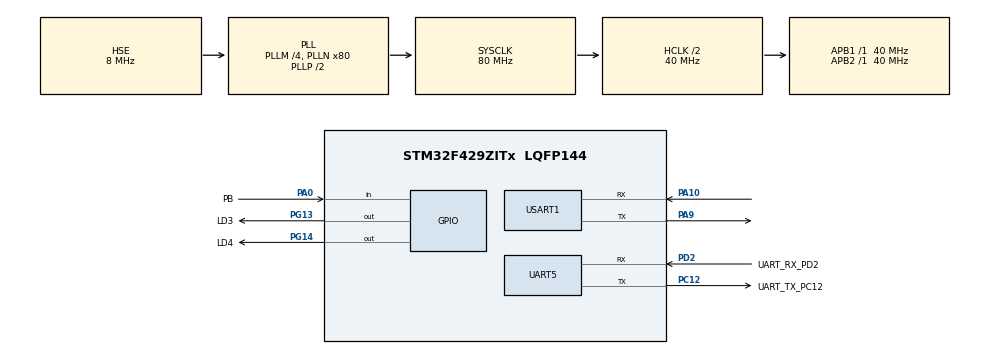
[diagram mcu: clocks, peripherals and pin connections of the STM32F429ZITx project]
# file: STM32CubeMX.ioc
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Mcu.Family=STM32F4
Mcu.Name=STM32F429ZITx
Mcu.Package=LQFP144
NVIC.PriorityGroup=NVIC_PRIORITYGROUP_4
PA0/WKUP.GPIO_Label=PB
PA0/WKUP.Signal=GPIO_Input
PA10.Mode=Asynchronous
PA10.Signal=USART1_RX
PA13.Mode=JTAG_4_pins
PA13.Signal=SYS_JTMS-SWDIO
PA14.Mode=JTAG_4_pins
PA14.Signal=SYS_JTCK-SWCLK
PA15.Mode=JTAG_4_pins
PA15.Signal=SYS_JTDI
PA9.Mode=Asynchronous
PA9.Signal=USART1_TX
PB3.Mode=JTAG_4_pins
PB3.Signal=SYS_JTDO-SWO
PC12.GPIO_Label=UART_TX_PC12
PC12.Mode=Asynchronous
PC12.Signal=UART5_TX
PD2.GPIO_Label=UART_RX_PD2
PD2.Mode=Asynchronous
PD2.Signal=UART5_RX
PG13.GPIO_Label=LD3
PG13.Signal=GPIO_Output
PG14.GPIO_Label=LD4
PG14.Signal=GPIO_Output
PH0/OSC_IN.Mode=HSE-External-Oscillator
PH0/OSC_IN.Signal=RCC_OSC_IN
PH1/OSC_OUT.Mode=HSE-External-Oscillator
PH1/OSC_OUT.Signal=RCC_OSC_OUT
ProjectManager.HeapSize=0x200
ProjectManager.StackSize=0x400
ProjectManager.TargetToolchain=MDK-ARM V5
RCC.48MHZClocksFreq_Value=40000000
RCC.AHBCLKDivider=RCC_SYSCLK_DIV2
RCC.AHBFreq_Value=40000000
RCC.APB1Freq_Value=40000000
RCC.APB1TimFreq_Value=40000000
RCC.APB2Freq_Value=40000000
RCC.APB2TimFreq_Value=40000000
RCC.CortexFreq_Value=40000000
RCC.HCLKFreq_Value=40000000
RCC.HSE_VALUE=8000000
RCC.HSI_VALUE=16000000
RCC.LSE_VALUE=32768
RCC.PLLM=4
RCC.PLLN=80
RCC.PLLSourceVirtual=RCC_PLLSOURCE_HSE
RCC.SYSCLKFreq_VALUE=80000000
RCC.SYSCLKSource=RCC_SYSCLKSOURCE_PLLCLK
RCC.VCOOutputFreq_Value=160000000
UART5.VirtualMode=Asynchronous
USART1.VirtualMode=VM_ASYNC
board=custom

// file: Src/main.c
/* USER CODE BEGIN Header */
/**
  ******************************************************************************
  * @file           : main.c
  * @brief          : Main program body
  ******************************************************************************
  * @attention
  *
  * Copyright (c) 2025 STMicroelectronics.
  * All rights reserved.
  *
  * This software is licensed under terms that can be found in the LICENSE file
  * in the root directory of this software component.
  * If no LICENSE file comes with this software, it is provided AS-IS.
  *
  ******************************************************************************
  */
/* USER CODE END Header */
#include "main.h"

/* USER CODE BEGIN Includes */
#include "uart.h"
#include "led.h"
/* USER CODE END Includes */

/* USER CODE BEGIN PTD */
Led_Type led1;
Led_Type led2;
/* USER CODE END PTD */

UART_HandleTypeDef huart5;
UART_HandleTypeDef huart1;

void SystemClock_Config(void);
static void MX_GPIO_Init(void);
static void MX_UART5_Init(void);
static void MX_USART1_UART_Init(void);

/* USER CODE BEGIN 0 */
char RData[15] = "Ramkumar\n\r";
/* USER CODE END 0 */

int main(void)
{

  /* MCU Configuration--------------------------------------------------------*/

  /* Reset of all peripherals, Initializes the Flash interface and the Systick. */
  HAL_Init();

  /* Configure the system clock */
  SystemClock_Config();

  /* Initialize all configured peripherals */
  MX_GPIO_Init();
  MX_UART5_Init();
  MX_USART1_UART_Init();

  /* Infinite loop */
  /* USER CODE BEGIN WHILE */
	printf("Hello there from main function\n\r");

	//HAL_UART_Transmit(&huart5, (uint8_t*)&RData, 1, HAL_MAX_DELAY);
	Led_ctor(&led1,RED,OFF);
	Led_ctor(&led2,GREEN,ON);

	Led_getState(&led1);
	Led_getState(&led2);

	Led_setState(&led1,ON);
	Led_setState(&led2,OFF);
  while (1)
  {
		//HAL_UART_Transmit(&huart5, (uint8_t*)RData, 20, HAL_MAX_DELAY);
		//printf("Hello there from main function\n\r");
		/*HAL_GPIO_ReadPin(GPIO_TypeDef* GPIOx, uint16_t GPIO_Pin)*/
	  //if(HAL_GPIO_ReadPin(GPIOA, PB_Pin))
		//  HAL_GPIO_WritePin(GPIOG, LD3_Pin, GPIO_PIN_SET);
	  //else
		//  HAL_GPIO_WritePin(GPIOG, LD3_Pin, GPIO_PIN_RESET);
    /* USER CODE END WHILE */

  }
}

void SystemClock_Config(void)
{
  RCC_OscInitTypeDef RCC_OscInitStruct = {0};
  RCC_ClkInitTypeDef RCC_ClkInitStruct = {0};

  /** Configure the main internal regulator output voltage
  */
  __HAL_RCC_PWR_CLK_ENABLE();
  __HAL_PWR_VOLTAGESCALING_CONFIG(PWR_REGULATOR_VOLTAGE_SCALE3);

  /** Initializes the RCC Oscillators according to the specified parameters
  * in the RCC_OscInitTypeDef structure.
  */
  RCC_OscInitStruct.OscillatorType = RCC_OSCILLATORTYPE_HSE;
  RCC_OscInitStruct.HSEState = RCC_HSE_ON;
  RCC_OscInitStruct.PLL.PLLState = RCC_PLL_ON;
  RCC_OscInitStruct.PLL.PLLSource = RCC_PLLSOURCE_HSE;
  RCC_OscInitStruct.PLL.PLLM = 4;
  RCC_OscInitStruct.PLL.PLLN = 80;
  RCC_OscInitStruct.PLL.PLLP = RCC_PLLP_DIV2;
  RCC_OscInitStruct.PLL.PLLQ = 4;
  if (HAL_RCC_OscConfig(&RCC_OscInitStruct) != HAL_OK)
  {
    Error_Handler();
  }

  /** Initializes the CPU, AHB and APB buses clocks
  */
  RCC_ClkInitStruct.ClockType = RCC_CLOCKTYPE_HCLK|RCC_CLOCKTYPE_SYSCLK
                              |RCC_CLOCKTYPE_PCLK1|RCC_CLOCKTYPE_PCLK2;
  RCC_ClkInitStruct.SYSCLKSource = RCC_SYSCLKSOURCE_PLLCLK;
  RCC_ClkInitStruct.AHBCLKDivider = RCC_SYSCLK_DIV2;
  RCC_ClkInitStruct.APB1CLKDivider = RCC_HCLK_DIV1;
  RCC_ClkInitStruct.APB2CLKDivider = RCC_HCLK_DIV1;

  if (HAL_RCC_ClockConfig(&RCC_ClkInitStruct, FLASH_LATENCY_1) != HAL_OK)
  {
    Error_Handler();
  }
}

static void MX_UART5_Init(void)
{

  huart5.Instance = UART5;
  huart5.Init.BaudRate = 115200;
  huart5.Init.WordLength = UART_WORDLENGTH_8B;
  huart5.Init.StopBits = UART_STOPBITS_1;
  huart5.Init.Parity = UART_PARITY_NONE;
  huart5.Init.Mode = UART_MODE_TX_RX;
  huart5.Init.HwFlowCtl = UART_HWCONTROL_NONE;
  huart5.Init.OverSampling = UART_OVERSAMPLING_16;
  if (HAL_UART_Init(&huart5) != HAL_OK)
  {
    Error_Handler();
  }

}

static void MX_USART1_UART_Init(void)
{

  huart1.Instance = USART1;
  huart1.Init.BaudRate = 115200;
  huart1.Init.WordLength = UART_WORDLENGTH_8B;
  huart1.Init.StopBits = UART_STOPBITS_1;
  huart1.Init.Parity = UART_PARITY_NONE;
  huart1.Init.Mode = UART_MODE_TX_RX;
  huart1.Init.HwFlowCtl = UART_HWCONTROL_NONE;
  huart1.Init.OverSampling = UART_OVERSAMPLING_16;
  if (HAL_UART_Init(&huart1) != HAL_OK)
  {
    Error_Handler();
  }

}

static void MX_GPIO_Init(void)
{
  GPIO_InitTypeDef GPIO_InitStruct = {0};

  /* GPIO Ports Clock Enable */
  __HAL_RCC_GPIOH_CLK_ENABLE();
  __HAL_RCC_GPIOA_CLK_ENABLE();
  __HAL_RCC_GPIOC_CLK_ENABLE();
  __HAL_RCC_GPIOD_CLK_ENABLE();
  __HAL_RCC_GPIOG_CLK_ENABLE();
  __HAL_RCC_GPIOB_CLK_ENABLE();

  /*Configure GPIO pin Output Level */
  HAL_GPIO_WritePin(GPIOG, LD3_Pin|LD4_Pin, GPIO_PIN_RESET);

  /*Configure GPIO pin : PB_Pin */
  GPIO_InitStruct.Pin = PB_Pin;
  GPIO_InitStruct.Mode = GPIO_MODE_INPUT;
  GPIO_InitStruct.Pull = GPIO_NOPULL;
  HAL_GPIO_Init(PB_GPIO_Port, &GPIO_InitStruct);

  /*Configure GPIO pins : LD3_Pin LD4_Pin */
  GPIO_InitStruct.Pin = LD3_Pin|LD4_Pin;
  GPIO_InitStruct.Mode = GPIO_MODE_OUTPUT_PP;
  GPIO_InitStruct.Pull = GPIO_NOPULL;
  GPIO_InitStruct.Speed = GPIO_SPEED_FREQ_LOW;
  HAL_GPIO_Init(GPIOG, &GPIO_InitStruct);

}

void Error_Handler(void)
{
  __disable_irq();
  while (1)
  {
  }
}
